# STM32F413CGU3 register map
File version: 1.0
Registers are 32-bit, access not given, reset 0x0 unless marked. A register's access mark holds for its fields unless they carry their own. Offsets are from the block's base; [hi:lo] are bit positions; {n}, {i} and the like mark numbered series.

## RCC
Base 0x40023800
0x00 CR
  [27] PLLI2SRDY, [26] PLLI2SON, [25] PLLRDY, [24] PLLON, [19] CSSON, [18] HSEBYP, [17] HSERDY, [16] HSEON, [15:8] HSICAL, [7:3] HSITRIM, [31:2] s, [1] HSIRDY, [0] HSION
0x04 PLLCFGR
  [30:28] PLLR, [27:24] PLLQ, [22] PLLSRC, [17:16] PLLP, [31:15] s, [14:6] PLLN, [5:0] PLLM
0x08 CFGR
  [31:30] MCO2, [29:27] MCO2PRE, [26:24] MCO1PRE, [22:21] MCO1, [20:16] RTCPRE, [15:13] PPRE2, [12:10] PPRE1, [23:8] s, [7:4] HPRE, [3:2] SWS, [1:0] SW
0x0C CIR
  [23] CSSC, [21] PLLI2SRDYC, [20] PLLRDYC, [19] HSERDYC, [18] HSIRDYC, [17] LSERDYC, [16] LSIRDYC, [13] PLLI2SRDYIE, [12] PLLRDYIE, [11] HSERDYIE, [10] HSIRDYIE, [9] LSERDYIE, [8] LSIRDYIE, [7] CSSF, [31:6] s, [5] PLLI2SRDYF, [4] PLLRDYF, [3] HSERDYF, [2] HSIRDYF, [1] LSERDYF, [0] LSIRDYF
0x10 AHB1RSTR
  [22] DMA2RST, [21] DMA1RST, [12] CRCRST, [31:8] s, [7] GPIOHRST, [6] GPIOGRST, [5] GPIOFRST, [4] GPIOERST, [3] GPIODRST, [2] GPIOCRST, [1] GPIOBRST, [0] GPIOARST
0x14 AHB2RSTR
  [7] OTGFSRST, [6] RNGRST, [4] CRYPRST, [31:0] s
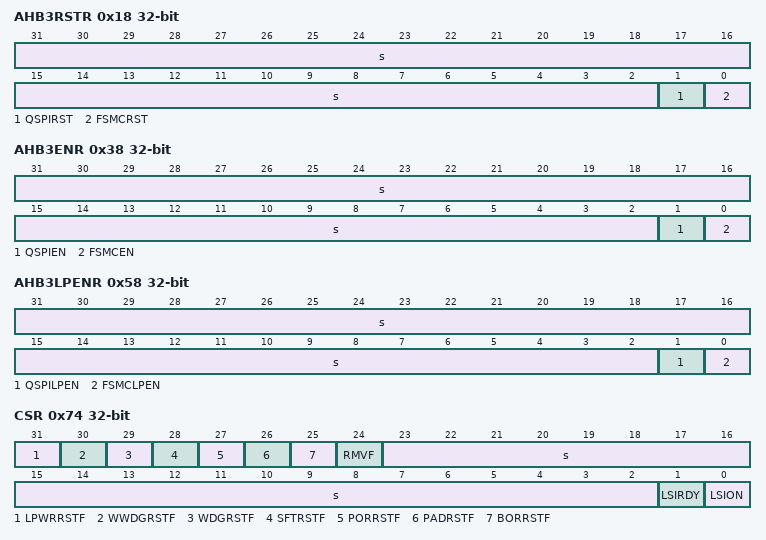
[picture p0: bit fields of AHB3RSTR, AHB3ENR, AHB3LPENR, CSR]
0x18 AHB3RSTR
  [31:2] s, [1] QSPIRST, [0] FSMCRST
0x20 APB1RSTR
  [31] UART8RST, [30] UART7RST, [29] DACRST, [28] PWRRST, [27] CAN3RST, [26] CAN2RST, [25] CAN1RST, [24] I2CFMP1RST, [23] I2C3RST, [22] I2C2RST, [21] I2C1RST, [20] UART5RST, [19] UART4RST, [18] USART3RST, [17] USART2RST, [15] SPI3RST, [14] SPI2RST, [11] WWDGRST, [16:10] s, [9] LPTIMER1RST, [8] TIM14RST, [7] TIM13RST, [6] TIM12RST, [n-2] TIM{n}RST (n=2..7)
0x24 APB2RSTR
  [25] DFSDM2RST, [24] DFSDM1RST, [22] SAI1RST, [20] SPI5RST, [18] TIM11RST, [17] TIM10RST, [16] TIM9RST, [14] SYSCFGRST, [13] SP45RST, [12] SPI1RST, [11] SDIORST, [8] ADCRST, [7] UART10RST, [6] UART9RST, [5] USART6RST, [4] USART1RST, [31:2] s, [1] TIM8RST, [0] TIM1RST
0x30 AHB1ENR
  [22] DMA2EN, [21] DMA1EN, [12] CRCEN, [31:8] s, [7] GPIOHEN, [6] GPIOGEN, [5] GPIOFEN, [4] GPIOEEN, [3] GPIODEN, [2] GPIOCEN, [1] GPIOBEN, [0] GPIOAEN
0x34 AHB2ENR
  [7] OTGFSEN, [6] RNGEN, [4] CRYPEN, [31:0] s
0x38 AHB3ENR
  [31:2] s, [1] QSPIEN, [0] FSMCEN
0x40 APB1ENR
  [31] UART8EN, [30] UART7EN, [29] DACEN, [28] PWREN, [27] CAN3EN, [26] CAN2EN, [25] CAN1EN, [24] I2CFMP1EN, [23] I2C3EN, [22] I2C2EN, [21] I2C1EN, [20] UART5EN, [19] UART4EN, [18] USART3EN, [17] USART2EN, [15] SPI3EN, [14] SPI2EN, [16:12] s, [11] WWDGEN, [10] RTCAPBEN, [9] LPTIMER1EN, [8] TIM14EN, [7] TIM13EN, [6] TIM12EN, [n-2] TIM{n}EN (n=2..7)
0x44 APB2ENR
  [25] DFSDM2EN, [24] DFSDM1EN, [22] SAI1EN, [20] SPI5EN, [18] TIM11EN, [17] TIM10EN, [16] TIM9EN, [14] SYSCFGEN, [13] SPI4EN, [12] SPI1EN, [11] SDIOEN, [8] ADC1EN, [7] UART10EN, [6] UART9EN, [5] USART6EN, [4] USART1EN, [31:2] s, [1] TIM8EN, [0] TIM1EN
0x50 AHB1LPENR
  [22] DMA2LPEN, [21] DMA1LPEN, [17] SRAM2LPEN, [16] SRAM1LPEN, [15] FLITFLPEN, [12] CRCLPEN, [31:8] s, [7] GPIOHLPEN, [6] GPIOGLPEN, [5] GPIOFLPEN, [4] GPIOELPEN, [3] GPIODLPEN, [2] GPIOCLPEN, [1] GPIOBLPEN, [0] GPIOALPEN
0x54 AHB2LPENR
  [7] OTGFSLPEN, [6] RNGLPEN, [4] CRYPLPEN, [31:0] s
0x58 AHB3LPENR
  [31:2] s, [1] QSPILPEN, [0] FSMCLPEN
0x60 APB1LPENR
  [31] UART8LPEN, [30] UART7LPEN, [29] DACLPEN, [28] PWRLPEN, [27] CAN3LPEN, [26] CAN2LPEN, [25] CAN1LPEN, [24] I2CFMP1LPEN, [23] I2C3LPEN, [22] I2C2LPEN, [21] I2C1LPEN, [20] UART5LPEN, [19] UART4LPEN, [18] USART3LPEN, [17] USART2LPEN, [15] SPI3LPEN, [14] SPI2LPEN, [11] WWDGLPEN, [16:10] s, [9] LPTIMER1EN, [8] TIM14LPEN, [7] TIM13LPEN, [6] TIM12LPEN, [n-2] TIM{n}LPEN (n=2..7)
0x64 APB2LPENR
  [25] DFSDM2LPEN, [24] DFSDM1LPEN, [21] SAI1LPEN, [20] SPI5LPEN, [18] TIM11LPEN, [17] TIM10LPEN, [16] TIM9LPEN, [15] EXTITEN, [14] SYSCFGLPEN, [13] SPI4LPEN, [12] SPI1LPEN, [11] SDIOLPEN, [8] ADC1LPEN, [7] UART10LPEN, [6] UART9LPEN, [5] USART6LPEN, [4] USART1LPEN, [31:2] s, [1] TIM8LPEN, [0] TIM1LPEN
0x70 BDCR
  [16] BDRST, [15] RTCEN, [9:8] RTCSEL, [31:4] s, [3] LSEMOD, [2] LSEBYP, [1] LSERDY, [0] LSEON
0x74 CSR
  [31] LPWRRSTF, [30] WWDGRSTF, [29] WDGRSTF, [28] SFTRSTF, [27] PORRSTF, [26] PADRSTF, [25] BORRSTF, [24] RMVF, [23:2] s, [1] LSIRDY, [0] LSION
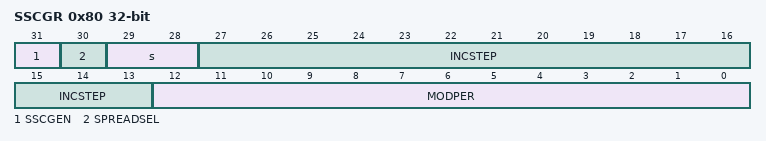
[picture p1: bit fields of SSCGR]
0x80 SSCGR
  [31] SSCGEN, [30] SPREADSEL, [29:28] s, [27:13] INCSTEP, [12:0] MODPER
0x84 PLLI2SCFGR
  [30:28] PLLI2SR, [27:24] PLLI2SQ, [22] PLLI2SSRC, [31:15] s, [14:6] PLLI2SN], [5:0] PLLI2SM
0x8C DCKCFGR
  [31] CKDFSDM1SEL, [28:27] I2S2SRC, [26:25] I2S1SRC, [24] TIMPRE, [23:22] SAI1BSR, [21:20] SAI1ASR, [15] CKDFSDM1ASEL, [14] CKDFSDM2ASEL, [12:8] PLLDIVR], [30:5] s, [4:0] PLLI2SDIVR]
0x94 DCKCFGR2
  [31] LPTIMER1SEL1, [30] LPTIMER1SEL0, [28] SDIOSEL, [27] CK48MSEL, [23:22] I2CFMP1SEL, [29:0] s
